AUTOSAR XML (schema 4-0-3)
package /ComponentTypes
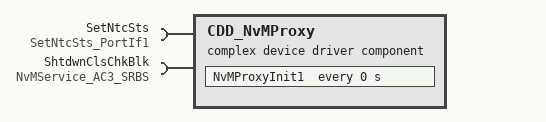
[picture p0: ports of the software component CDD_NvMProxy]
  complex device driver sw component type CDD_NvMProxy
    require port SetNtcSts: client-com-spec=Oper, required-interface=SetNtcSts_PortIf1
    require port ShtdwnClsChkBlk: required-com-specs=[EraseBlock, GetErrorStatus, InvalidateNvBlock, ReadBlock, SetRamBlockStatus, WriteBlock], required-interface=NvMService_AC3_SRBS
    behavior CDD_NvMProxy_InternalBehavior
      ar-typed-per-instance-memorys:
        5 x data, all with sw-calibration-access=READ-ONLY:
          BlkFltTbl: type=Ary1D_BlkFltTblRec1_5
          CmdRtnBuf: type=Ary1D_CmdRtnBufRec1_NvMProxy1
          NvmBlkActv: type=Ary1D_boolean_NvMProxy1
          NvmStsCollctd: type=boolean
          ShtdwnClsChk: type=uint32
      timing event NvMProxy_InitEvent: start-on-event=NvMProxyInit1, period=0
      runnable NvMProxyInit1
        sync call SC_SetNtcSts_Oper: operation=SetNtcSts.Oper, timeout=0
      swc service dependency ShtdwnClsChkBlk: assigned-datas=role-based-data-assignment={role=ramBlock, used-data-element=ShtdwnClsChk}
        assigned-ports:
          port-prototype=ShtdwnClsChkBlk, role=NvMService_AC3_SRBS
          port-prototype=ShtdwnClsChkBlk, role=NvMService_AC3_SRBS
        service-needs:
          nv block needs ShtdwnClsChkBlk: n-data-sets=0, readonly=false, reliability=ERROR-DETECTION, resistant-to-changed-sw=true, restore-at-start=true, store-at-shutdown=true, write-only-once=false, writing-frequency=0, writing-priority=LOW
  swc implementation CDD_NvMProxy_Implementation: behavior=CDD_NvMProxy_InternalBehavior
    code-descriptors:
      code Default: artifact-descriptors=autosar-engineering-object={short-label=Default, category=SWSRC}
